AUTOSAR XML (schema 4-0-3)
package /AUTOLIV/SoftwareComponents/BFS
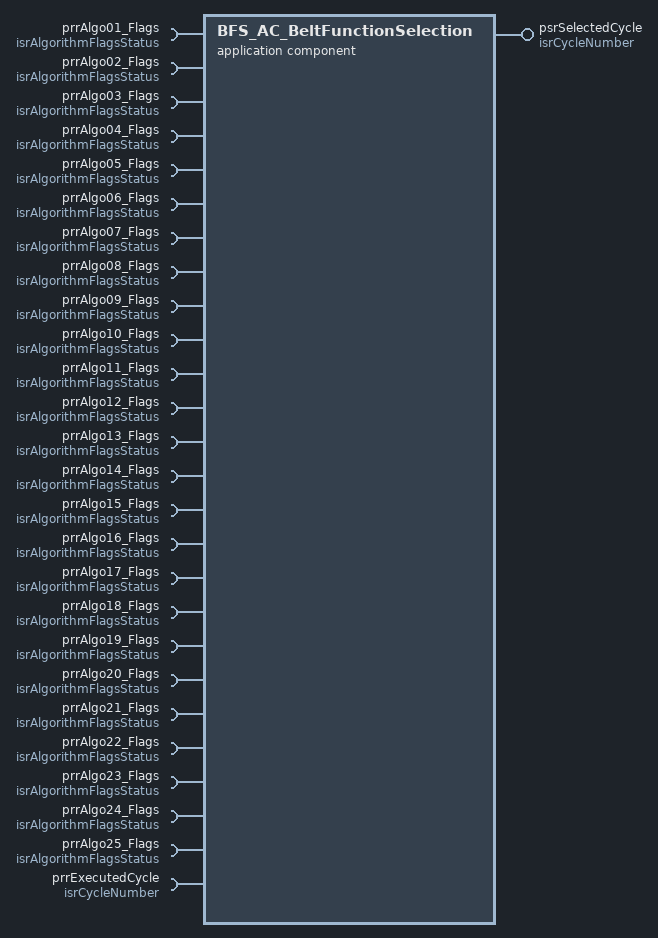
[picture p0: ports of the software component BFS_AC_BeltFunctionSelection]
  application sw component type BFS_AC_BeltFunctionSelection: category=SWC
    26 x require port:
      prrAlgo01_Flags: required-interface=isrAlgorithmFlagsStatus
        required-com-specs:
          data-element=b8TriggerFlag, uses-end-to-end-protection=0, init-value=constant-reference=APPLINIT_KB8_ALGO_FLAG_FALSE
          data-element=b8InterruptFlag, uses-end-to-end-protection=0, init-value=constant-reference=APPLINIT_KB8_ALGO_FLAG_FALSE
          data-element=b8PreActivationFlag, uses-end-to-end-protection=0, init-value=constant-reference=APPLINIT_KB8_ALGO_FLAG_FALSE
          data-element=b8PreConditionsFlag, uses-end-to-end-protection=0, init-value=constant-reference=APPLINIT_KB8_ALGO_FLAG_FALSE
          data-element=u8TriggeringSource, uses-end-to-end-protection=0, init-value=constant-reference=APPLINIT_KU8_TRIGGERING_SOURCE_NO
      prrAlgo02_Flags: required-interface=isrAlgorithmFlagsStatus
        required-com-specs:
          data-element=b8TriggerFlag, uses-end-to-end-protection=0, init-value=constant-reference=APPLINIT_KB8_ALGO_FLAG_FALSE
          data-element=b8InterruptFlag, uses-end-to-end-protection=0, init-value=constant-reference=APPLINIT_KB8_ALGO_FLAG_FALSE
          data-element=b8PreActivationFlag, uses-end-to-end-protection=0, init-value=constant-reference=APPLINIT_KB8_ALGO_FLAG_FALSE
          data-element=b8PreConditionsFlag, uses-end-to-end-protection=0, init-value=constant-reference=APPLINIT_KB8_ALGO_FLAG_FALSE
          data-element=u8TriggeringSource, uses-end-to-end-protection=0, init-value=constant-reference=APPLINIT_KU8_TRIGGERING_SOURCE_NO
      prrAlgo03_Flags: required-interface=isrAlgorithmFlagsStatus
        required-com-specs:
          data-element=b8TriggerFlag, uses-end-to-end-protection=0, init-value=constant-reference=APPLINIT_KB8_ALGO_FLAG_FALSE
          data-element=b8InterruptFlag, uses-end-to-end-protection=0, init-value=constant-reference=APPLINIT_KB8_ALGO_FLAG_FALSE
          data-element=b8PreActivationFlag, uses-end-to-end-protection=0, init-value=constant-reference=APPLINIT_KB8_ALGO_FLAG_FALSE
          data-element=b8PreConditionsFlag, uses-end-to-end-protection=0, init-value=constant-reference=APPLINIT_KB8_ALGO_FLAG_FALSE
          data-element=u8TriggeringSource, uses-end-to-end-protection=0, init-value=constant-reference=APPLINIT_KU8_TRIGGERING_SOURCE_NO
      prrAlgo04_Flags: required-interface=isrAlgorithmFlagsStatus
        required-com-specs:
          data-element=b8TriggerFlag, uses-end-to-end-protection=0, init-value=constant-reference=APPLINIT_KB8_ALGO_FLAG_FALSE
          data-element=b8InterruptFlag, uses-end-to-end-protection=0, init-value=constant-reference=APPLINIT_KB8_ALGO_FLAG_FALSE
          data-element=b8PreActivationFlag, uses-end-to-end-protection=0, init-value=constant-reference=APPLINIT_KB8_ALGO_FLAG_FALSE
          data-element=b8PreConditionsFlag, uses-end-to-end-protection=0, init-value=constant-reference=APPLINIT_KB8_ALGO_FLAG_FALSE
          data-element=u8TriggeringSource, uses-end-to-end-protection=0, init-value=constant-reference=APPLINIT_KU8_TRIGGERING_SOURCE_NO
      prrAlgo05_Flags: required-interface=isrAlgorithmFlagsStatus
        required-com-specs:
          data-element=b8TriggerFlag, uses-end-to-end-protection=0, init-value=constant-reference=APPLINIT_KB8_ALGO_FLAG_FALSE
          data-element=b8InterruptFlag, uses-end-to-end-protection=0, init-value=constant-reference=APPLINIT_KB8_ALGO_FLAG_FALSE
          data-element=b8PreActivationFlag, uses-end-to-end-protection=0, init-value=constant-reference=APPLINIT_KB8_ALGO_FLAG_FALSE
          data-element=b8PreConditionsFlag, uses-end-to-end-protection=0, init-value=constant-reference=APPLINIT_KB8_ALGO_FLAG_FALSE
          data-element=u8TriggeringSource, uses-end-to-end-protection=0, init-value=constant-reference=APPLINIT_KU8_TRIGGERING_SOURCE_NO
      prrAlgo06_Flags: required-interface=isrAlgorithmFlagsStatus
        required-com-specs:
          data-element=b8TriggerFlag, uses-end-to-end-protection=0, init-value=constant-reference=APPLINIT_KB8_ALGO_FLAG_FALSE
          data-element=b8InterruptFlag, uses-end-to-end-protection=0, init-value=constant-reference=APPLINIT_KB8_ALGO_FLAG_FALSE
          data-element=b8PreActivationFlag, uses-end-to-end-protection=0, init-value=constant-reference=APPLINIT_KB8_ALGO_FLAG_FALSE
          data-element=b8PreConditionsFlag, uses-end-to-end-protection=0, init-value=constant-reference=APPLINIT_KB8_ALGO_FLAG_FALSE
          data-element=u8TriggeringSource, uses-end-to-end-protection=0, init-value=constant-reference=APPLINIT_KU8_TRIGGERING_SOURCE_NO
      prrAlgo07_Flags: required-interface=isrAlgorithmFlagsStatus
        required-com-specs:
          data-element=b8TriggerFlag, uses-end-to-end-protection=0, init-value=constant-reference=APPLINIT_KB8_ALGO_FLAG_FALSE
          data-element=b8InterruptFlag, uses-end-to-end-protection=0, init-value=constant-reference=APPLINIT_KB8_ALGO_FLAG_FALSE
          data-element=b8PreActivationFlag, uses-end-to-end-protection=0, init-value=constant-reference=APPLINIT_KB8_ALGO_FLAG_FALSE
          data-element=b8PreConditionsFlag, uses-end-to-end-protection=0, init-value=constant-reference=APPLINIT_KB8_ALGO_FLAG_FALSE
          data-element=u8TriggeringSource, uses-end-to-end-protection=0, init-value=constant-reference=APPLINIT_KU8_TRIGGERING_SOURCE_NO
      prrAlgo08_Flags: required-interface=isrAlgorithmFlagsStatus
        required-com-specs:
          data-element=b8TriggerFlag, uses-end-to-end-protection=0, init-value=constant-reference=APPLINIT_KB8_ALGO_FLAG_FALSE
          data-element=b8InterruptFlag, uses-end-to-end-protection=0, init-value=constant-reference=APPLINIT_KB8_ALGO_FLAG_FALSE
          data-element=b8PreActivationFlag, uses-end-to-end-protection=0, init-value=constant-reference=APPLINIT_KB8_ALGO_FLAG_FALSE
          data-element=b8PreConditionsFlag, uses-end-to-end-protection=0, init-value=constant-reference=APPLINIT_KB8_ALGO_FLAG_FALSE
          data-element=u8TriggeringSource, uses-end-to-end-protection=0, init-value=constant-reference=APPLINIT_KU8_TRIGGERING_SOURCE_NO
      prrAlgo09_Flags: required-interface=isrAlgorithmFlagsStatus
        required-com-specs:
          data-element=b8TriggerFlag, uses-end-to-end-protection=0, init-value=constant-reference=APPLINIT_KB8_ALGO_FLAG_FALSE
          data-element=b8InterruptFlag, uses-end-to-end-protection=0, init-value=constant-reference=APPLINIT_KB8_ALGO_FLAG_FALSE
          data-element=b8PreActivationFlag, uses-end-to-end-protection=0, init-value=constant-reference=APPLINIT_KB8_ALGO_FLAG_FALSE
          data-element=b8PreConditionsFlag, uses-end-to-end-protection=0, init-value=constant-reference=APPLINIT_KB8_ALGO_FLAG_FALSE
          data-element=u8TriggeringSource, uses-end-to-end-protection=0, init-value=constant-reference=APPLINIT_KU8_TRIGGERING_SOURCE_NO
      prrAlgo10_Flags: required-interface=isrAlgorithmFlagsStatus
        required-com-specs:
          data-element=b8TriggerFlag, uses-end-to-end-protection=0, init-value=constant-reference=APPLINIT_KB8_ALGO_FLAG_FALSE
          data-element=b8InterruptFlag, uses-end-to-end-protection=0, init-value=constant-reference=APPLINIT_KB8_ALGO_FLAG_FALSE
          data-element=b8PreActivationFlag, uses-end-to-end-protection=0, init-value=constant-reference=APPLINIT_KB8_ALGO_FLAG_FALSE
          data-element=b8PreConditionsFlag, uses-end-to-end-protection=0, init-value=constant-reference=APPLINIT_KB8_ALGO_FLAG_FALSE
          data-element=u8TriggeringSource, uses-end-to-end-protection=0, init-value=constant-reference=APPLINIT_KU8_TRIGGERING_SOURCE_NO
      prrAlgo11_Flags: required-interface=isrAlgorithmFlagsStatus
        required-com-specs:
          data-element=b8TriggerFlag, uses-end-to-end-protection=0, init-value=constant-reference=APPLINIT_KB8_ALGO_FLAG_FALSE
          data-element=b8InterruptFlag, uses-end-to-end-protection=0, init-value=constant-reference=APPLINIT_KB8_ALGO_FLAG_FALSE
          data-element=b8PreActivationFlag, uses-end-to-end-protection=0, init-value=constant-reference=APPLINIT_KB8_ALGO_FLAG_FALSE
          data-element=b8PreConditionsFlag, uses-end-to-end-protection=0, init-value=constant-reference=APPLINIT_KB8_ALGO_FLAG_FALSE
          data-element=u8TriggeringSource, uses-end-to-end-protection=0, init-value=constant-reference=APPLINIT_KU8_TRIGGERING_SOURCE_NO
      prrAlgo12_Flags: required-interface=isrAlgorithmFlagsStatus
        required-com-specs:
          data-element=b8TriggerFlag, uses-end-to-end-protection=0, init-value=constant-reference=APPLINIT_KB8_ALGO_FLAG_FALSE
          data-element=b8InterruptFlag, uses-end-to-end-protection=0, init-value=constant-reference=APPLINIT_KB8_ALGO_FLAG_FALSE
          data-element=b8PreActivationFlag, uses-end-to-end-protection=0, init-value=constant-reference=APPLINIT_KB8_ALGO_FLAG_FALSE
          data-element=b8PreConditionsFlag, uses-end-to-end-protection=0, init-value=constant-reference=APPLINIT_KB8_ALGO_FLAG_FALSE
          data-element=u8TriggeringSource, uses-end-to-end-protection=0, init-value=constant-reference=APPLINIT_KU8_TRIGGERING_SOURCE_NO
      prrAlgo13_Flags: required-interface=isrAlgorithmFlagsStatus
        required-com-specs:
          data-element=b8TriggerFlag, uses-end-to-end-protection=0, init-value=constant-reference=APPLINIT_KB8_ALGO_FLAG_FALSE
          data-element=b8InterruptFlag, uses-end-to-end-protection=0, init-value=constant-reference=APPLINIT_KB8_ALGO_FLAG_FALSE
          data-element=b8PreActivationFlag, uses-end-to-end-protection=0, init-value=constant-reference=APPLINIT_KB8_ALGO_FLAG_FALSE
          data-element=b8PreConditionsFlag, uses-end-to-end-protection=0, init-value=constant-reference=APPLINIT_KB8_ALGO_FLAG_FALSE
          data-element=u8TriggeringSource, uses-end-to-end-protection=0, init-value=constant-reference=APPLINIT_KU8_TRIGGERING_SOURCE_NO
      prrAlgo14_Flags: required-interface=isrAlgorithmFlagsStatus
        required-com-specs:
          data-element=b8TriggerFlag, uses-end-to-end-protection=0, init-value=constant-reference=APPLINIT_KB8_ALGO_FLAG_FALSE
          data-element=b8InterruptFlag, uses-end-to-end-protection=0, init-value=constant-reference=APPLINIT_KB8_ALGO_FLAG_FALSE
          data-element=b8PreActivationFlag, uses-end-to-end-protection=0, init-value=constant-reference=APPLINIT_KB8_ALGO_FLAG_FALSE
          data-element=b8PreConditionsFlag, uses-end-to-end-protection=0, init-value=constant-reference=APPLINIT_KB8_ALGO_FLAG_FALSE
          data-element=u8TriggeringSource, uses-end-to-end-protection=0, init-value=constant-reference=APPLINIT_KU8_TRIGGERING_SOURCE_NO
      prrAlgo15_Flags: required-interface=isrAlgorithmFlagsStatus
        required-com-specs:
          data-element=b8TriggerFlag, uses-end-to-end-protection=0, init-value=constant-reference=APPLINIT_KB8_ALGO_FLAG_FALSE
          data-element=b8InterruptFlag, uses-end-to-end-protection=0, init-value=constant-reference=APPLINIT_KB8_ALGO_FLAG_FALSE
          data-element=b8PreActivationFlag, uses-end-to-end-protection=0, init-value=constant-reference=APPLINIT_KB8_ALGO_FLAG_FALSE
          data-element=b8PreConditionsFlag, uses-end-to-end-protection=0, init-value=constant-reference=APPLINIT_KB8_ALGO_FLAG_FALSE
          data-element=u8TriggeringSource, uses-end-to-end-protection=0, init-value=constant-reference=APPLINIT_KU8_TRIGGERING_SOURCE_NO
      prrAlgo16_Flags: required-interface=isrAlgorithmFlagsStatus
        required-com-specs:
          data-element=b8TriggerFlag, uses-end-to-end-protection=0, init-value=constant-reference=APPLINIT_KB8_ALGO_FLAG_FALSE
          data-element=b8InterruptFlag, uses-end-to-end-protection=0, init-value=constant-reference=APPLINIT_KB8_ALGO_FLAG_FALSE
          data-element=b8PreActivationFlag, uses-end-to-end-protection=0, init-value=constant-reference=APPLINIT_KB8_ALGO_FLAG_FALSE
          data-element=b8PreConditionsFlag, uses-end-to-end-protection=0, init-value=constant-reference=APPLINIT_KB8_ALGO_FLAG_FALSE
          data-element=u8TriggeringSource, uses-end-to-end-protection=0, init-value=constant-reference=APPLINIT_KU8_TRIGGERING_SOURCE_NO
      prrAlgo17_Flags: required-interface=isrAlgorithmFlagsStatus
        required-com-specs:
          data-element=b8TriggerFlag, uses-end-to-end-protection=0, init-value=constant-reference=APPLINIT_KB8_ALGO_FLAG_FALSE
          data-element=b8InterruptFlag, uses-end-to-end-protection=0, init-value=constant-reference=APPLINIT_KB8_ALGO_FLAG_FALSE
          data-element=b8PreActivationFlag, uses-end-to-end-protection=0, init-value=constant-reference=APPLINIT_KB8_ALGO_FLAG_FALSE
          data-element=b8PreConditionsFlag, uses-end-to-end-protection=0, init-value=constant-reference=APPLINIT_KB8_ALGO_FLAG_FALSE
          data-element=u8TriggeringSource, uses-end-to-end-protection=0, init-value=constant-reference=APPLINIT_KU8_TRIGGERING_SOURCE_NO
      prrAlgo18_Flags: required-interface=isrAlgorithmFlagsStatus
        required-com-specs:
          data-element=b8TriggerFlag, uses-end-to-end-protection=0, init-value=constant-reference=APPLINIT_KB8_ALGO_FLAG_FALSE
          data-element=b8InterruptFlag, uses-end-to-end-protection=0, init-value=constant-reference=APPLINIT_KB8_ALGO_FLAG_FALSE
          data-element=b8PreActivationFlag, uses-end-to-end-protection=0, init-value=constant-reference=APPLINIT_KB8_ALGO_FLAG_FALSE
          data-element=b8PreConditionsFlag, uses-end-to-end-protection=0, init-value=constant-reference=APPLINIT_KB8_ALGO_FLAG_FALSE
          data-element=u8TriggeringSource, uses-end-to-end-protection=0, init-value=constant-reference=APPLINIT_KU8_TRIGGERING_SOURCE_NO
      prrAlgo19_Flags: required-interface=isrAlgorithmFlagsStatus
        required-com-specs:
          data-element=b8TriggerFlag, uses-end-to-end-protection=0, init-value=constant-reference=APPLINIT_KB8_ALGO_FLAG_FALSE
          data-element=b8InterruptFlag, uses-end-to-end-protection=0, init-value=constant-reference=APPLINIT_KB8_ALGO_FLAG_FALSE
          data-element=b8PreActivationFlag, uses-end-to-end-protection=0, init-value=constant-reference=APPLINIT_KB8_ALGO_FLAG_FALSE
          data-element=b8PreConditionsFlag, uses-end-to-end-protection=0, init-value=constant-reference=APPLINIT_KB8_ALGO_FLAG_FALSE
          data-element=u8TriggeringSource, uses-end-to-end-protection=0, init-value=constant-reference=APPLINIT_KU8_TRIGGERING_SOURCE_NO
      prrAlgo20_Flags: required-interface=isrAlgorithmFlagsStatus
        required-com-specs:
          data-element=b8TriggerFlag, uses-end-to-end-protection=0, init-value=constant-reference=APPLINIT_KB8_ALGO_FLAG_FALSE
          data-element=b8InterruptFlag, uses-end-to-end-protection=0, init-value=constant-reference=APPLINIT_KB8_ALGO_FLAG_FALSE
          data-element=b8PreActivationFlag, uses-end-to-end-protection=0, init-value=constant-reference=APPLINIT_KB8_ALGO_FLAG_FALSE
          data-element=b8PreConditionsFlag, uses-end-to-end-protection=0, init-value=constant-reference=APPLINIT_KB8_ALGO_FLAG_FALSE
          data-element=u8TriggeringSource, uses-end-to-end-protection=0, init-value=constant-reference=APPLINIT_KU8_TRIGGERING_SOURCE_NO
      prrAlgo21_Flags: required-interface=isrAlgorithmFlagsStatus
        required-com-specs:
          data-element=b8TriggerFlag, uses-end-to-end-protection=0, init-value=constant-reference=APPLINIT_KB8_ALGO_FLAG_FALSE
          data-element=b8InterruptFlag, uses-end-to-end-protection=0, init-value=constant-reference=APPLINIT_KB8_ALGO_FLAG_FALSE
          data-element=b8PreActivationFlag, uses-end-to-end-protection=0, init-value=constant-reference=APPLINIT_KB8_ALGO_FLAG_FALSE
          data-element=b8PreConditionsFlag, uses-end-to-end-protection=0, init-value=constant-reference=APPLINIT_KB8_ALGO_FLAG_FALSE
          data-element=u8TriggeringSource, uses-end-to-end-protection=0, init-value=constant-reference=APPLINIT_KU8_TRIGGERING_SOURCE_NO
      prrAlgo22_Flags: required-interface=isrAlgorithmFlagsStatus
        required-com-specs:
          data-element=b8TriggerFlag, uses-end-to-end-protection=0, init-value=constant-reference=APPLINIT_KB8_ALGO_FLAG_FALSE
          data-element=b8InterruptFlag, uses-end-to-end-protection=0, init-value=constant-reference=APPLINIT_KB8_ALGO_FLAG_FALSE
          data-element=b8PreActivationFlag, uses-end-to-end-protection=0, init-value=constant-reference=APPLINIT_KB8_ALGO_FLAG_FALSE
          data-element=b8PreConditionsFlag, uses-end-to-end-protection=0, init-value=constant-reference=APPLINIT_KB8_ALGO_FLAG_FALSE
          data-element=u8TriggeringSource, uses-end-to-end-protection=0, init-value=constant-reference=APPLINIT_KU8_TRIGGERING_SOURCE_NO
      prrAlgo23_Flags: required-interface=isrAlgorithmFlagsStatus
        required-com-specs:
          data-element=b8TriggerFlag, uses-end-to-end-protection=0, init-value=constant-reference=APPLINIT_KB8_ALGO_FLAG_FALSE
          data-element=b8InterruptFlag, uses-end-to-end-protection=0, init-value=constant-reference=APPLINIT_KB8_ALGO_FLAG_FALSE
          data-element=b8PreActivationFlag, uses-end-to-end-protection=0, init-value=constant-reference=APPLINIT_KB8_ALGO_FLAG_FALSE
          data-element=b8PreConditionsFlag, uses-end-to-end-protection=0, init-value=constant-reference=APPLINIT_KB8_ALGO_FLAG_FALSE
          data-element=u8TriggeringSource, uses-end-to-end-protection=0, init-value=constant-reference=APPLINIT_KU8_TRIGGERING_SOURCE_NO
      prrAlgo24_Flags: required-interface=isrAlgorithmFlagsStatus
        required-com-specs:
          data-element=b8TriggerFlag, uses-end-to-end-protection=0, init-value=constant-reference=APPLINIT_KB8_ALGO_FLAG_FALSE
          data-element=b8InterruptFlag, uses-end-to-end-protection=0, init-value=constant-reference=APPLINIT_KB8_ALGO_FLAG_FALSE
          data-element=b8PreActivationFlag, uses-end-to-end-protection=0, init-value=constant-reference=APPLINIT_KB8_ALGO_FLAG_FALSE
          data-element=b8PreConditionsFlag, uses-end-to-end-protection=0, init-value=constant-reference=APPLINIT_KB8_ALGO_FLAG_FALSE
          data-element=u8TriggeringSource, uses-end-to-end-protection=0, init-value=constant-reference=APPLINIT_KU8_TRIGGERING_SOURCE_NO
      prrAlgo25_Flags: required-interface=isrAlgorithmFlagsStatus
        required-com-specs:
          data-element=b8TriggerFlag, uses-end-to-end-protection=0, init-value=constant-reference=APPLINIT_KB8_ALGO_FLAG_FALSE
          data-element=b8InterruptFlag, uses-end-to-end-protection=0, init-value=constant-reference=APPLINIT_KB8_ALGO_FLAG_FALSE
          data-element=b8PreActivationFlag, uses-end-to-end-protection=0, init-value=constant-reference=APPLINIT_KB8_ALGO_FLAG_FALSE
          data-element=b8PreConditionsFlag, uses-end-to-end-protection=0, init-value=constant-reference=APPLINIT_KB8_ALGO_FLAG_FALSE
          data-element=u8TriggeringSource, uses-end-to-end-protection=0, init-value=constant-reference=APPLINIT_KU8_TRIGGERING_SOURCE_NO
      prrExecutedCycle: nonqueued-receiver-com-spec{data-element=u8CycleNumber, uses-end-to-end-protection=0, init-value=constant-reference=APPLINIT_KU8_CYCLE_NUMBER_NONE}, required-interface=isrCycleNumber
    provide port psrSelectedCycle: nonqueued-sender-com-spec{data-element=u8CycleNumber, uses-end-to-end-protection=0, init-value=constant-reference=APPLINIT_KU8_CYCLE_NUMBER_NONE}, provided-interface=isrCycleNumber
